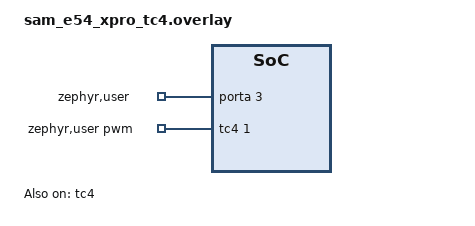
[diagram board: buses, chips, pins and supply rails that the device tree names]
/*
 * Copyright (c) 2025 Microchip Technology Inc.
 *
 * SPDX-License-Identifier: Apache-2.0
 */

/* connect the PA23 to PA03 */

#include <zephyr/dt-bindings/gpio/gpio.h>

/ {
	zephyr,user {
		pwms = <&tc4 1 PWM_MSEC(1) 0>;
		gpios = <&porta 3 GPIO_ACTIVE_HIGH>;
	};
};

&tc4 {
	status = "okay";
	compatible = "microchip,tc-g1-pwm";
	#pwm-cells = <3>;
	pinctrl-0 = <&tc4_pwm_default>;
	pinctrl-names = "default";
	prescaler = <4>;
};

&porta {
	status = "okay";
};

&pinctrl {
	tc4_pwm_default: tc4_pwm_default {
		group1 {
			pinmux = <PA23E_TC4_WO1>;
		};
	};
};
